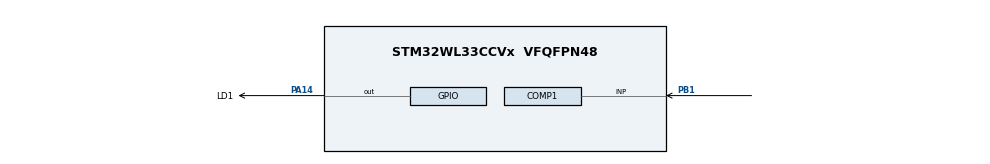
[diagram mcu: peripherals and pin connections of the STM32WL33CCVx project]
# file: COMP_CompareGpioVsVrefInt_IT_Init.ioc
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COMP1.TriggerMode=COMP_TRIGGERMODE_RISING_FALLING
Mcu.Family=STM32WL3
Mcu.Name=STM32WL33CCVx
Mcu.Package=VFQFPN48
NVIC.COMP1_IRQn=true\:0\:0\:false\:false\:true\:true\:true\:true
OSCIN.Mode=HSE-External-Oscillator
OSCIN.Signal=RCC_OSC_IN
OSCOUT.Mode=HSE-External-Oscillator
OSCOUT.Signal=RCC_OSC_OUT
PA14.GPIO_Label=LD1
PA14.Signal=GPIO_Output
PB1.Mode=INP
PB1.Signal=COMP1_INP
ProjectManager.HeapSize=0x000
ProjectManager.StackSize=0xC00
ProjectManager.TargetToolchain=EWARM V9.30
RCC.HSE_VALUE=48000000
RCC.HSI_VALUE=64000000
RCC.LSE_VALUE=32768
RCC.RC64MPLLSource=RCC_LSCOSOURCE_PLL64
VP_COMP1_VS_VREFINT.Mode=VREFINT
VP_PWR_VS_SECSignals.Mode=Security/Privilege
board=custom

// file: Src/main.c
/* USER CODE BEGIN Header */
/**
  ******************************************************************************
  * @file    Examples_LL/COMP/COMP_CompareGpioVsVrefInt_IT_Init/Src/main.c
  * @author  MCD Application Team
  * @brief   How to use a comparator peripheral to compare a voltage level
  *          on a GPIO pin versus the internal voltage reference (VrefInt),
  *          in interrupt mode.
  *          This example is based on the STM32WL3x COMP LL API;
  *          Peripheral initialization done using LL unitary services functions.
  ******************************************************************************
  * @attention
  *
  * Copyright (c) 2024 STMicroelectronics.
  * All rights reserved.
  *
  * This software is licensed under terms that can be found in the LICENSE file
  * in the root directory of this software component.
  * If no LICENSE file comes with this software, it is provided AS-IS.
  *
  ******************************************************************************
  */
/* USER CODE END Header */
#include "main.h"

void SystemClock_Config(void);
void PeriphCommonClock_Config(void);
static void MX_GPIO_Init(void);
static void MX_COMP1_Init(void);
/* USER CODE BEGIN PFP */

void Activate_COMP(void);
void LED_On(void);
void LED_Off(void);
void LED_Toggle(void);

/* USER CODE END PFP */

int main(void)
{

  /* MCU Configuration--------------------------------------------------------*/

  /* Reset of all peripherals, Initializes the Flash interface and the Systick. */
  LL_APB0_GRP1_EnableClock(LL_APB0_GRP1_PERIPH_SYSCFG);

  /* SysTick_IRQn interrupt configuration */
  NVIC_SetPriority(SysTick_IRQn, 3);

  /* Configure the system clock */
  SystemClock_Config();

  /* Configure the peripherals common clocks */
  PeriphCommonClock_Config();

  /* Initialize all configured peripherals */
  MX_GPIO_Init();
  MX_COMP1_Init();
  /* USER CODE BEGIN 2 */

  /* Activate comparator */
  Activate_COMP();

  /* Lock comparator instance */
  /* Note: Comparator lock is optional, to protect against any unexpected
           program action on comparator configuration
           (for example, due to program counter corruption). */
  //LL_COMP_Lock(COMP1);

  /* USER CODE END 2 */

  /* Infinite loop */
  /* USER CODE BEGIN WHILE */
  while (1)
  {
    /* Note: LED state indicates comparator output state and is set into      */
    /*       comparator IRQ handler, refer to function                        */
    /*       "ComparatorTrigger_Callback()".                                  */

    /* USER CODE END WHILE */

  }
}

void SystemClock_Config(void)
{

   /* Set HSE Capacitor Tuning */
  LL_RCC_HSE_SetCapacitorTuning(CFG_HW_RCC_HSE_CAPACITOR_TUNE);

   /* Set HSE startup Current */
 LL_RCC_HSE_SetStartupCurrent(0);

   /* Set HSE Amplitude Threshold */
 LL_RCC_HSE_SetAmplitudeThreshold(0);

   /* Set HSE Current Control */
  LL_RCC_HSE_SetCurrentControl(40);

   /* Enable the HSE */
  LL_RCC_HSE_Enable();

   /* Wait till HSE is ready */
  while(LL_RCC_HSE_IsReady() != 1)
  {
  }

  LL_FLASH_SetLatency(LL_FLASH_WAIT_STATES_1);

   /* Enable the RC64MPLL*/
  LL_RCC_RC64MPLL_Enable();

   /* Wait till RC64MPLL is ready */
  while(LL_RCC_RC64MPLL_IsReady() != 1)
  {
  }

  LL_RCC_SetRC64MPLLPrescaler(LL_RCC_RC64MPLL_DIV_1);

   /* Update the SystemCoreClock global variable */
  LL_SetSystemCoreClock(64000000);

   /* Configure the source of time base considering new system clocks settings*/
  LL_Init1msTick(64000000);
}

void PeriphCommonClock_Config(void)
{
  LL_RCC_SetSMPSPrescaler(LL_RCC_SMPS_DIV_2);

   /* Enable the KRM*/
  LL_RCC_KRM_Enable();
  LL_RCC_KRM_SetRateMultiplier(2);
}

static void MX_COMP1_Init(void)
{

  LL_COMP_InitTypeDef COMP_InitStruct = {0};

  LL_GPIO_InitTypeDef GPIO_InitStruct = {0};

  /* Peripheral clock enable */
  LL_APB0_GRP1_EnableClock(LL_APB0_GRP1_PERIPH_COMP);

  LL_AHB1_GRP1_EnableClock(LL_AHB1_GRP1_PERIPH_GPIOB);
  /**COMP1 GPIO Configuration
  PB1   ------> COMP1_INP
  */
  GPIO_InitStruct.Pin = LL_GPIO_PIN_1;
  GPIO_InitStruct.Mode = LL_GPIO_MODE_ANALOG;
  GPIO_InitStruct.Pull = LL_GPIO_PULL_NO;
  LL_GPIO_Init(GPIOB, &GPIO_InitStruct);

  /* COMP1 interrupt Init */
  NVIC_SetPriority(COMP1_IRQn, 0);
  NVIC_EnableIRQ(COMP1_IRQn);

  COMP_InitStruct.PowerMode = LL_COMP_POWERMODE_HIGHSPEED;
  COMP_InitStruct.InputPlus = LL_COMP_INPUT_PLUS_IO2;
  COMP_InitStruct.InputMinus = LL_COMP_INPUT_MINUS_VREFINT;
  COMP_InitStruct.InputHysteresis = LL_COMP_HYSTERESIS_NONE;
  COMP_InitStruct.OutputPolarity = LL_COMP_OUTPUTPOL_NONINVERTED;
  COMP_InitStruct.OutputBlankingSource = LL_COMP_BLANKINGSRC_NONE;
  LL_COMP_Init(COMP1, &COMP_InitStruct);

  /* Wait loop initialization and execution */
  /* Note: Variable divided by 2 to compensate partially CPU processing cycles */
  __IO uint32_t wait_loop_index = 0;
  wait_loop_index = (LL_COMP_DELAY_VOLTAGE_SCALER_STAB_US * (SystemCoreClock / (1000000 * 2)));
  while(wait_loop_index != 0)
  {
    wait_loop_index--;
  }
  /* USER CODE BEGIN COMP1_Init 2 */
  LL_SYSCFG_MR_SUBG_INTAI_SetTrigger(LL_SYSCFG_MR_SUBG_TRIGGER_BOTH_EDGE, LL_SYSCFG_MR_SUBG_COMPOUT_EVENT);
  /* Clear COMP EXTI pending bit (if any) */
  LL_SYSCFG_MR_SUBG_INTAI_ClearInterrupt(LL_SYSCFG_MR_SUBG_COMPOUT_EVENT);
  LL_SYSCFG_MR_SUBG_INTAI_EnableIT(LL_SYSCFG_MR_SUBG_COMPOUT_EVENT);
  /* USER CODE END COMP1_Init 2 */

}

static void MX_GPIO_Init(void)
{
  LL_GPIO_InitTypeDef GPIO_InitStruct = {0};

  /* GPIO Ports Clock Enable */
  LL_AHB1_GRP1_EnableClock(LL_AHB1_GRP1_PERIPH_GPIOA);
  LL_AHB1_GRP1_EnableClock(LL_AHB1_GRP1_PERIPH_GPIOB);

  /**/
  LL_GPIO_ResetOutputPin(LD1_GPIO_Port, LD1_Pin);

  /**/
  GPIO_InitStruct.Pin = LD1_Pin;
  GPIO_InitStruct.Mode = LL_GPIO_MODE_OUTPUT;
  GPIO_InitStruct.Speed = LL_GPIO_SPEED_FREQ_LOW;
  GPIO_InitStruct.OutputType = LL_GPIO_OUTPUT_PUSHPULL;
  GPIO_InitStruct.Pull = LL_GPIO_PULL_NO;
  LL_GPIO_Init(LD1_GPIO_Port, &GPIO_InitStruct);

}

/* USER CODE BEGIN 4 */

/**
  * @brief  Perform comparator activation procedure
  *         (COMP instance: COMP1).
  * @param  None
  * @retval None
  */
void Activate_COMP(void)
{
  __IO uint32_t wait_loop_index = 0;

  /* Enable comparator */
  LL_COMP_Enable(COMP1);

  /* Delay for comparator startup time.                                       */
  /* Compute number of CPU cycles to wait for, from delay in us.              */
  /* Note: Variable divided by 2 to compensate partially                      */
  /*       CPU processing cycles (depends on compilation optimization).       */
  /* Note: If system clock frequency is below 200kHz, wait time will          */
  /*       correspond to the few CPU processing cycles to process this        */
  /*       calculation.                                                       */
  wait_loop_index = ((LL_COMP_DELAY_STARTUP_US * (SystemCoreClock / (100000 * 2))) / 10);
  while(wait_loop_index != 0)
  {
    wait_loop_index--;
  }
}

/**
  * @brief  Turn-on LD1.
  * @param  None
  * @retval None
  */
void LED_On(void)
{
  /* Turn LED on */
  LL_GPIO_ResetOutputPin(LD1_GPIO_Port, LD1_Pin);
}

/**
  * @brief  Turn-off LD1.
  * @param  None
  * @retval None
  */
void LED_Off(void)
{
  /* Turn LED off */
  LL_GPIO_SetOutputPin(LD1_GPIO_Port, LD1_Pin);
}

/**
  * @brief  Toggle LD1.
  * @param  None
  * @retval None
  */
void LED_Toggle(void)
{
  /* Turn LED off */
  LL_GPIO_TogglePin(LD1_GPIO_Port, LD1_Pin);
}

/******************************************************************************/
/*   USER IRQ HANDLER TREATMENT                                               */
/******************************************************************************/

/**
  * @brief  Comparator interruption callback
  * @note   This function is called when comparator threshold is triggered.
  * @retval None
  */
void ComparatorTrigger_Callback()
{
  /* Set LED state in function of comparator output level */
  if (LL_COMP_ReadOutputLevel(COMP1) == LL_COMP_OUTPUT_LEVEL_HIGH)
  {
    LED_On();
  }
  else
  {
    LED_Off();
  }
}

/* USER CODE END 4 */

void Error_Handler(void)
{
  /* USER CODE BEGIN Error_Handler_Debug */
  /* User can add his own implementation to report the HAL error return state */

  /* Turn on LED and remain in infinite loop */
  while (1)
  {
    LED_On();
  }
  /* USER CODE END Error_Handler_Debug */
}
